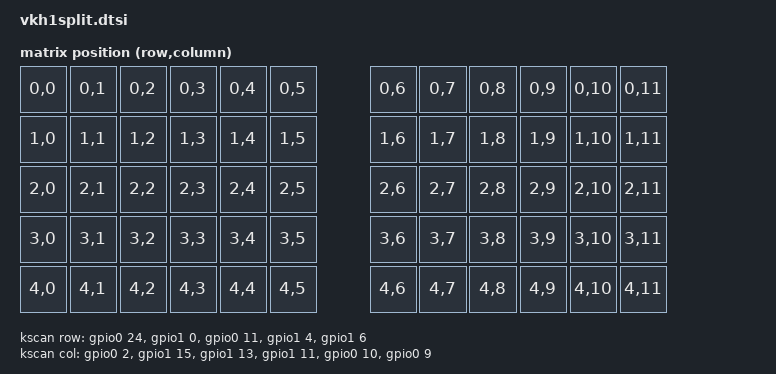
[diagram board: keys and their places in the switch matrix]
// This file was generated from a template. Edit it to match your keyboard.
// See https://zmk.dev/docs/development/hardware-integration/new-shield for more
// instructions.

#include <dt-bindings/zmk/matrix_transform.h>

#include "vkh1split-layouts.dtsi"

/ {
    chosen {
        zmk,kscan = &kscan;
        zmk,physical-layout = &default_layout;
    };

    kscan: kscan {
        // If the hardware does not use a switch matrix, change this to the
        // appropriate driver and update the properties below to match.
        // See https://zmk.dev/docs/config/kscan for supported key scan drivers.
        compatible = "zmk,kscan-gpio-matrix";
        // Set this to "col2row" or "row2col" to match the hardware. If using
        // "row2col", change the col-gpios in the _left.overlay and _right.overlay
        // files to (GPIO_ACTIVE_HIGH | GPIO_PULL_DOWN) and the row-gpios here to
        // GPIO_ACTIVE_HIGH.
        diode-direction = "col2row";
        wakeup-source;

        // Replace these comments with the GPIO pins in the matrix.
        // See https://zmk.dev/docs/development/hardware-integration/new-shield#shield-overlays
        row-gpios
            = <&gpio0 24 (GPIO_ACTIVE_HIGH | GPIO_PULL_DOWN)> // p0.24
            , <&gpio1 0 (GPIO_ACTIVE_HIGH | GPIO_PULL_DOWN)>  // p1.00
            , <&gpio0 11 (GPIO_ACTIVE_HIGH | GPIO_PULL_DOWN)> // p0.11
            , <&gpio1 4 (GPIO_ACTIVE_HIGH | GPIO_PULL_DOWN)>  // p1.04
            , <&gpio1 6 (GPIO_ACTIVE_HIGH | GPIO_PULL_DOWN)>  // p1.06
            ;
        col-gpios
            = <&gpio0 2 GPIO_ACTIVE_HIGH>  // P0.02
            , <&gpio1 15 GPIO_ACTIVE_HIGH> // P1.15
            , <&gpio1 13 GPIO_ACTIVE_HIGH> // P1.13
            , <&gpio1 11 GPIO_ACTIVE_HIGH> // P1.11
            , <&gpio0 10 GPIO_ACTIVE_HIGH> // P0.10
            , <&gpio0 9 GPIO_ACTIVE_HIGH>  // P0.09
            ;

        // QMK configuration:
        // "matrix_pins": {
        //     "cols": [
        //         "F6",  // 0 -> P0.02
        //         "F7",  // 1 -> P1.15
        //         "B1",  // 2 -> P1.13
        //         "B3",  // 3 -> P1.11
        //         "B2",  // 4 -> P0.10
        //         "B6"   // 5 -> P0.09
        //     ],
        //     "rows": [
        //         "C6",  // 0 -> p0.24
        //         "D7",  // 1 -> p1.00
        //         "E6",  // 2 -> p0.11
        //         "B4",  // 3 -> p1.04
        //         "B5"   // 4 -> p1.06
        //     ]
        // }
    };

    default_transform: default_transform {
        // See https://zmk.dev/docs/development/hardware-integration/new-shield#matrix-transform
        // for how to configure this
        compatible = "zmk,matrix-transform";
        columns = <6>;
        rows = <5>;

        map = <
            RC(0, 0) RC(0, 1) RC(0, 2) RC(0, 3) RC(0, 4) RC(0, 5)           RC(0, 6) RC(0, 7) RC(0, 8) RC(0, 9) RC(0, 10) RC(0, 11)
            RC(1, 0) RC(1, 1) RC(1, 2) RC(1, 3) RC(1, 4) RC(1, 5)           RC(1, 6) RC(1, 7) RC(1, 8) RC(1, 9) RC(1, 10) RC(1, 11)
            RC(2, 0) RC(2, 1) RC(2, 2) RC(2, 3) RC(2, 4) RC(2, 5)           RC(2, 6) RC(2, 7) RC(2, 8) RC(2, 9) RC(2, 10) RC(2, 11)
            RC(3, 0) RC(3, 1) RC(3, 2) RC(3, 3) RC(3, 4) RC(3, 5)           RC(3, 6) RC(3, 7) RC(3, 8) RC(3, 9) RC(3, 10) RC(3, 11)
            RC(4, 0) RC(4, 1) RC(4, 2) RC(4, 3) RC(4, 4) RC(4, 5)           RC(4, 6) RC(4, 7) RC(4, 8) RC(4, 9) RC(4, 10) RC(4, 11)
        >;
    };
};
